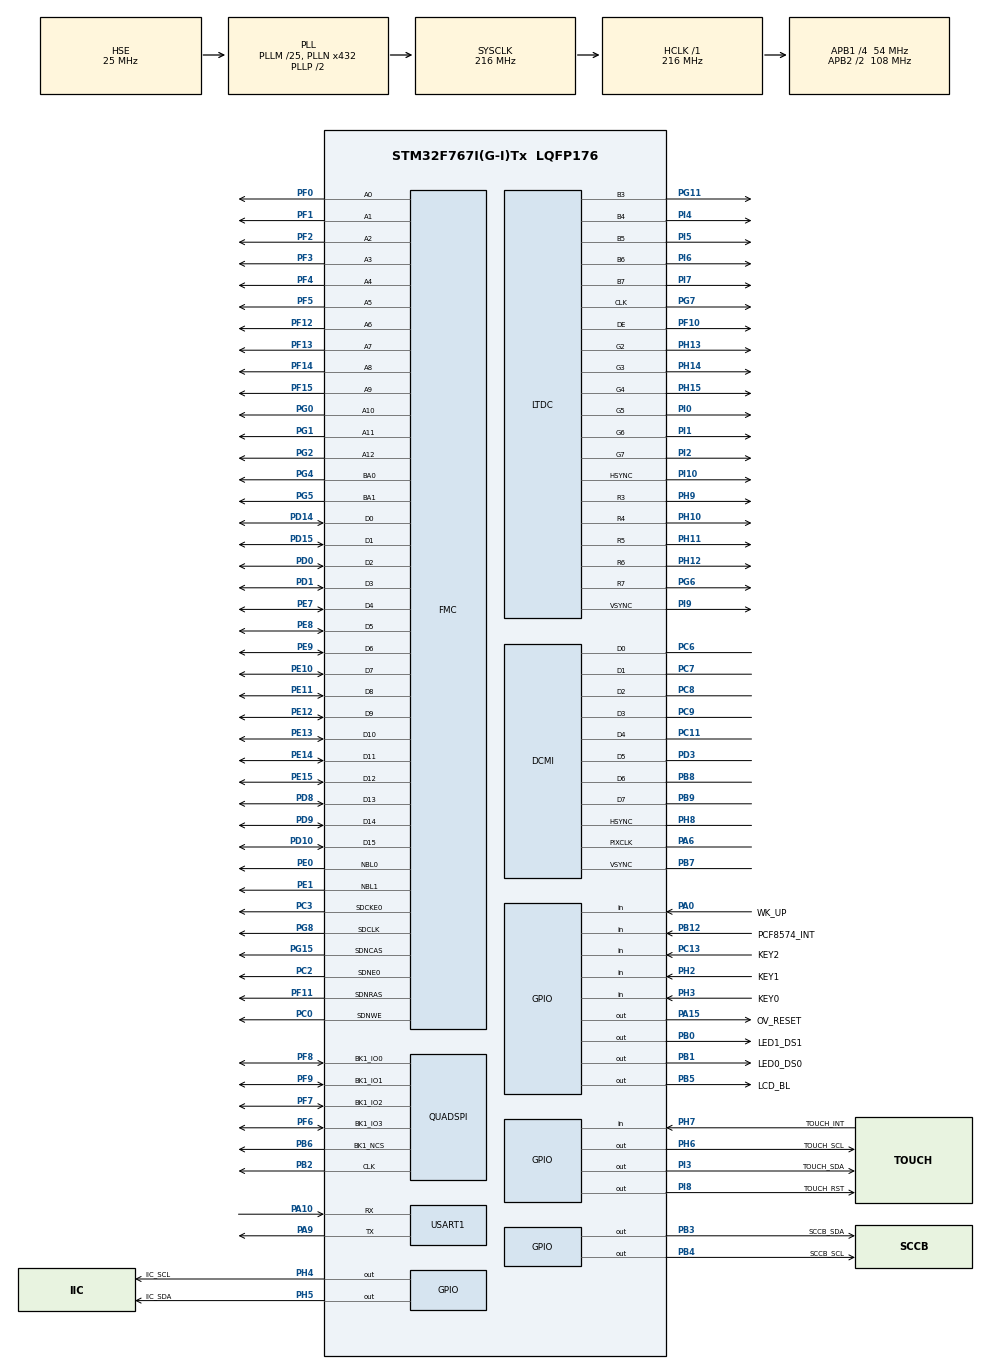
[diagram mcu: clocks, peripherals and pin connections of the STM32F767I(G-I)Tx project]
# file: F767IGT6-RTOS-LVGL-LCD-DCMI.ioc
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CORTEX_M7.default_mode_Activation=1
DCMI.HSPolarity=DCMI_HSPOLARITY_LOW
DCMI.JPEGMode=DCMI_JPEG_DISABLE
DCMI.PCKPolarity=DCMI_PCKPOLARITY_RISING
DCMI.VSPolarity=DCMI_VSPOLARITY_LOW
FMC.CASLatency1=FMC_SDRAM_CAS_LATENCY_3
FMC.ColumnBitsNumber1=FMC_SDRAM_COLUMN_BITS_NUM_9
FMC.ExitSelfRefreshDelay1=8
FMC.LoadToActiveDelay1=2
FMC.RCDDelay1=2
FMC.RPDelay1=2
FMC.ReadBurst1=FMC_SDRAM_RBURST_ENABLE
FMC.ReadPipeDelay1=FMC_SDRAM_RPIPE_DELAY_1
FMC.RowBitsNumber1=FMC_SDRAM_ROW_BITS_NUM_13
FMC.RowCycleDelay1=6
FMC.SDBank1=FMC_SDRAM_BANK1
FMC.SDClockPeriod1=FMC_SDRAM_CLOCK_PERIOD_2
FMC.SelfRefreshTime1=6
FMC.WriteRecoveryTime1=2
FMC.WriteProtection1=FMC_SDRAM_WRITE_PROTECTION_DISABLE
LTDC.ActiveW=1024
LTDC.ActiveH=600
LTDC.HSync=20
LTDC.HBP=140
LTDC.HFP=160
LTDC.VSync=3
LTDC.VBP=20
LTDC.VFP=12
LTDC.Layers=1
LTDC.WindowX0_L0=0
LTDC.WindowX1_L0=424
LTDC.WindowY0_L0=0
LTDC.WindowY1_L0=600
LTDC.PixelFormat_L0=LTDC_PIXEL_FORMAT_RGB565
LTDC.Alpha_L0=255
LTDC.Alpha0_L0=0
LTDC.BlendingFactor1_L0=LTDC_BLENDING_FACTOR1_PAxCA
LTDC.BlendingFactor2_L0=LTDC_BLENDING_FACTOR2_PAxCA
LTDC.FBStartAdress_L0=0xC0000000
LTDC.ImageWidth_L0=424
LTDC.ImageHeight_L0=600
LTDC.WindowX0_L1=424
LTDC.WindowX1_L1=1024
LTDC.WindowY0_L1=0
LTDC.WindowY1_L1=600
LTDC.PixelFormat_L1=LTDC_PIXEL_FORMAT_RGB565
LTDC.Alpha_L1=255
LTDC.Alpha0_L1=0
LTDC.BlendingFactor1_L1=LTDC_BLENDING_FACTOR1_PAxCA
LTDC.BlendingFactor2_L1=LTDC_BLENDING_FACTOR2_PAxCA
LTDC.FBStartAdress_L1=0xC0140000
LTDC.ImageWidth_L1=600
LTDC.ImageHeight_L1=600
Mcu.Family=STM32F7
Mcu.Name=STM32F767I(G-I)Tx
Mcu.Package=LQFP176
NVIC.DCMI_IRQn=true\:2\:0\:false\:false\:true\:true\:true\:true
NVIC.DMA2_Stream1_IRQn=true\:2\:0\:false\:false\:true\:true\:true\:true
NVIC.PriorityGroup=NVIC_PRIORITYGROUP_4
NVIC.TIM7_IRQn=true\:15\:0\:false\:false\:true\:false\:true\:true
NVIC.TimeBase=TIM7_IRQn
NVIC.TimeBaseIP=TIM7
PA0/WKUP.GPIO_Label=WK_UP
PA0/WKUP.GPIO_PuPd=GPIO_PULLDOWN
PA0/WKUP.Signal=GPIO_Input
PA10.Mode=Asynchronous
PA10.Signal=USART1_RX
PA13.Mode=Serial_Wire
PA13.Signal=SYS_JTMS-SWDIO
PA14.Mode=Serial_Wire
PA14.Signal=SYS_JTCK-SWCLK
PA15.GPIO_Label=OV_RESET
PA15.GPIO_PuPd=GPIO_PULLUP
PA15.GPIO_Speed=GPIO_SPEED_FREQ_HIGH
PA15.Signal=GPIO_Output
PA6.Mode=Slave_8_bits_External_Synchro
PA6.GPIO_Mode=GPIO_MODE_AF_PP
PA6.GPIO_PuPd=GPIO_PULLUP
PA6.GPIO_Speed=GPIO_SPEED_FREQ_VERY_HIGH
PA6.Signal=DCMI_PIXCLK
PA9.Mode=Asynchronous
PA9.Signal=USART1_TX
PB0.GPIO_Label=LED1_DS1
PB0.GPIO_PuPd=GPIO_PULLUP
PB0.GPIO_Speed=GPIO_SPEED_FREQ_HIGH
PB0.Signal=GPIO_Output
PB1.GPIO_Label=LED0_DS0
PB1.GPIO_PuPd=GPIO_PULLUP
PB1.GPIO_Speed=GPIO_SPEED_FREQ_HIGH
PB1.Signal=GPIO_Output
PB12.GPIO_Label=PCF8574_INT
PB12.GPIO_PuPd=GPIO_PULLUP
PB12.Signal=GPIO_Input
PB2.Mode=Single Bank 1
PB2.Signal=QUADSPI_CLK
PB3.GPIO_Label=SCCB_SDA
PB3.GPIO_PuPd=GPIO_PULLUP
PB3.GPIO_Speed=GPIO_SPEED_FREQ_HIGH
PB3.Signal=GPIO_Output
PB4.GPIO_Label=SCCB_SCL
PB4.GPIO_PuPd=GPIO_PULLUP
PB4.GPIO_Speed=GPIO_SPEED_FREQ_HIGH
PB4.Signal=GPIO_Output
PB5.GPIO_Label=LCD_BL
PB5.GPIO_PuPd=GPIO_PULLUP
PB5.GPIO_Speed=GPIO_SPEED_FREQ_HIGH
PB5.Signal=GPIO_Output
PB6.Mode=Single Bank 1
PB6.Signal=QUADSPI_BK1_NCS
PB7.Mode=Slave_8_bits_External_Synchro
PB7.GPIO_Mode=GPIO_MODE_AF_PP
PB7.GPIO_PuPd=GPIO_PULLUP
PB7.GPIO_Speed=GPIO_SPEED_FREQ_VERY_HIGH
PB7.Signal=DCMI_VSYNC
PB8.Mode=Slave_8_bits_External_Synchro
PB8.GPIO_Mode=GPIO_MODE_AF_PP
PB8.GPIO_PuPd=GPIO_PULLUP
PB8.GPIO_Speed=GPIO_SPEED_FREQ_VERY_HIGH
PB8.Signal=DCMI_D6
PB9.Mode=Slave_8_bits_External_Synchro
PB9.GPIO_Mode=GPIO_MODE_AF_PP
PB9.GPIO_PuPd=GPIO_PULLUP
PB9.GPIO_Speed=GPIO_SPEED_FREQ_VERY_HIGH
PB9.Signal=DCMI_D7
PC0.Signal=FMC_SDNWE
PC11.Mode=Slave_8_bits_External_Synchro
PC11.GPIO_Mode=GPIO_MODE_AF_PP
PC11.GPIO_PuPd=GPIO_PULLUP
PC11.GPIO_Speed=GPIO_SPEED_FREQ_VERY_HIGH
PC11.Signal=DCMI_D4
PC13.GPIO_Label=KEY2
PC13.GPIO_PuPd=GPIO_PULLUP
PC13.Signal=GPIO_Input
PC14/OSC32_IN.Mode=LSE-External-Oscillator
PC14/OSC32_IN.Signal=RCC_OSC32_IN
PC15/OSC32_OUT.Mode=LSE-External-Oscillator
PC15/OSC32_OUT.Signal=RCC_OSC32_OUT
PC2.Mode=SdramChipSelect1_1
PC2.Signal=FMC_SDNE0
PC3.Mode=SdramChipSelect1_1
PC3.Signal=FMC_SDCKE0
PC6.Mode=Slave_8_bits_External_Synchro
PC6.GPIO_Mode=GPIO_MODE_AF_PP
PC6.GPIO_PuPd=GPIO_PULLUP
PC6.GPIO_Speed=GPIO_SPEED_FREQ_VERY_HIGH
PC6.Signal=DCMI_D0
PC7.Mode=Slave_8_bits_External_Synchro
PC7.GPIO_Mode=GPIO_MODE_AF_PP
PC7.GPIO_PuPd=GPIO_PULLUP
PC7.GPIO_Speed=GPIO_SPEED_FREQ_VERY_HIGH
PC7.Signal=DCMI_D1
PC8.Mode=Slave_8_bits_External_Synchro
PC8.GPIO_Mode=GPIO_MODE_AF_PP
PC8.GPIO_PuPd=GPIO_PULLUP
PC8.GPIO_Speed=GPIO_SPEED_FREQ_VERY_HIGH
PC8.Signal=DCMI_D2
PC9.Mode=Slave_8_bits_External_Synchro
PC9.GPIO_Mode=GPIO_MODE_AF_PP
PC9.GPIO_PuPd=GPIO_PULLUP
PC9.GPIO_Speed=GPIO_SPEED_FREQ_VERY_HIGH
PC9.Signal=DCMI_D3
PD0.Signal=FMC_D2_DA2
PD1.Signal=FMC_D3_DA3
PD10.Signal=FMC_D15_DA15
PD14.Signal=FMC_D0_DA0
PD15.Signal=FMC_D1_DA1
PD3.Mode=Slave_8_bits_External_Synchro
PD3.GPIO_Mode=GPIO_MODE_AF_PP
PD3.GPIO_PuPd=GPIO_PULLUP
PD3.GPIO_Speed=GPIO_SPEED_FREQ_VERY_HIGH
PD3.Signal=DCMI_D5
PD8.Signal=FMC_D13_DA13
PD9.Signal=FMC_D14_DA14
PE0.Signal=FMC_NBL0
PE1.Signal=FMC_NBL1
PE10.Signal=FMC_D7_DA7
PE11.Signal=FMC_D8_DA8
PE12.Signal=FMC_D9_DA9
PE13.Signal=FMC_D10_DA10
PE14.Signal=FMC_D11_DA11
PE15.Signal=FMC_D12_DA12
PE7.Signal=FMC_D4_DA4
PE8.Signal=FMC_D5_DA5
PE9.Signal=FMC_D6_DA6
PF0.Signal=FMC_A0
PF1.Signal=FMC_A1
PF10.Mode=RGB565
PF10.GPIO_Mode=GPIO_MODE_AF_PP
PF10.GPIO_PuPd=GPIO_NOPULL
PF10.GPIO_Speed=GPIO_SPEED_FREQ_VERY_HIGH
PF10.Signal=LTDC_DE
PF11.Signal=FMC_SDNRAS
PF12.Signal=FMC_A6
PF13.Signal=FMC_A7
PF14.Signal=FMC_A8
PF15.Signal=FMC_A9
PF2.Signal=FMC_A2
PF3.Signal=FMC_A3
PF4.Signal=FMC_A4
PF5.Signal=FMC_A5
PF6.Mode=Single Bank 1
PF6.Signal=QUADSPI_BK1_IO3
PF7.Mode=Single Bank 1
PF7.Signal=QUADSPI_BK1_IO2
PF8.Mode=Single Bank 1
PF8.Signal=QUADSPI_BK1_IO0
PF9.Mode=Single Bank 1
PF9.Signal=QUADSPI_BK1_IO1
PG0.Signal=FMC_A10
PG1.Signal=FMC_A11
PG11.Mode=RGB565
PG11.GPIO_Mode=GPIO_MODE_AF_PP
PG11.GPIO_PuPd=GPIO_NOPULL
PG11.GPIO_Speed=GPIO_SPEED_FREQ_VERY_HIGH
PG11.Signal=LTDC_B3
PG15.Signal=FMC_SDNCAS
PG2.Signal=FMC_A12
PG4.Signal=FMC_A14_BA0
PG5.Signal=FMC_A15_BA1
PG6.Mode=RGB565
PG6.GPIO_Mode=GPIO_MODE_AF_PP
PG6.GPIO_PuPd=GPIO_NOPULL
PG6.GPIO_Speed=GPIO_SPEED_FREQ_VERY_HIGH
PG6.Signal=LTDC_R7
PG7.Mode=RGB565
PG7.GPIO_Mode=GPIO_MODE_AF_PP
PG7.GPIO_PuPd=GPIO_NOPULL
PG7.GPIO_Speed=GPIO_SPEED_FREQ_VERY_HIGH
PG7.Signal=LTDC_CLK
PG8.Signal=FMC_SDCLK
PH0/OSC_IN.Mode=HSE-External-Oscillator
PH0/OSC_IN.Signal=RCC_OSC_IN
PH1/OSC_OUT.Mode=HSE-External-Oscillator
PH1/OSC_OUT.Signal=RCC_OSC_OUT
PH10.Mode=RGB565
PH10.GPIO_Mode=GPIO_MODE_AF_PP
PH10.GPIO_PuPd=GPIO_NOPULL
PH10.GPIO_Speed=GPIO_SPEED_FREQ_VERY_HIGH
PH10.Signal=LTDC_R4
PH11.Mode=RGB565
PH11.GPIO_Mode=GPIO_MODE_AF_PP
PH11.GPIO_PuPd=GPIO_NOPULL
PH11.GPIO_Speed=GPIO_SPEED_FREQ_VERY_HIGH
PH11.Signal=LTDC_R5
PH12.Mode=RGB565
PH12.GPIO_Mode=GPIO_MODE_AF_PP
PH12.GPIO_PuPd=GPIO_NOPULL
PH12.GPIO_Speed=GPIO_SPEED_FREQ_VERY_HIGH
PH12.Signal=LTDC_R6
PH13.Mode=RGB565
PH13.GPIO_Mode=GPIO_MODE_AF_PP
PH13.GPIO_PuPd=GPIO_NOPULL
PH13.GPIO_Speed=GPIO_SPEED_FREQ_VERY_HIGH
PH13.Signal=LTDC_G2
PH14.Mode=RGB565
PH14.GPIO_Mode=GPIO_MODE_AF_PP
PH14.GPIO_PuPd=GPIO_NOPULL
PH14.GPIO_Speed=GPIO_SPEED_FREQ_VERY_HIGH
PH14.Signal=LTDC_G3
PH15.Mode=RGB565
PH15.GPIO_Mode=GPIO_MODE_AF_PP
PH15.GPIO_PuPd=GPIO_NOPULL
PH15.GPIO_Speed=GPIO_SPEED_FREQ_VERY_HIGH
PH15.Signal=LTDC_G4
PH2.GPIO_Label=KEY1
PH2.GPIO_PuPd=GPIO_PULLUP
PH2.Signal=GPIO_Input
PH3.GPIO_Label=KEY0
PH3.GPIO_PuPd=GPIO_PULLUP
PH3.Signal=GPIO_Input
PH4.GPIO_Label=IIC_SCL
PH4.GPIO_PuPd=GPIO_PULLUP
PH4.GPIO_Speed=GPIO_SPEED_FREQ_HIGH
PH4.Signal=GPIO_Output
PH5.GPIO_Label=IIC_SDA
PH5.GPIO_PuPd=GPIO_PULLUP
PH5.GPIO_Speed=GPIO_SPEED_FREQ_HIGH
PH5.Signal=GPIO_Output
PH8.Mode=Slave_8_bits_External_Synchro
PH8.GPIO_Mode=GPIO_MODE_AF_PP
PH8.GPIO_PuPd=GPIO_PULLUP
PH8.GPIO_Speed=GPIO_SPEED_FREQ_VERY_HIGH
PH8.Signal=DCMI_HSYNC
PH9.Mode=RGB565
PH9.GPIO_Mode=GPIO_MODE_AF_PP
PH9.GPIO_PuPd=GPIO_NOPULL
PH9.GPIO_Speed=GPIO_SPEED_FREQ_VERY_HIGH
PH9.Signal=LTDC_R3
PI0.Mode=RGB565
PI0.GPIO_Mode=GPIO_MODE_AF_PP
PI0.GPIO_PuPd=GPIO_NOPULL
PI0.GPIO_Speed=GPIO_SPEED_FREQ_VERY_HIGH
PI0.Signal=LTDC_G5
PI1.Mode=RGB565
PI1.GPIO_Mode=GPIO_MODE_AF_PP
PI1.GPIO_PuPd=GPIO_NOPULL
PI1.GPIO_Speed=GPIO_SPEED_FREQ_VERY_HIGH
PI1.Signal=LTDC_G6
PI10.Mode=RGB565
PI10.GPIO_Mode=GPIO_MODE_AF_PP
PI10.GPIO_PuPd=GPIO_NOPULL
PI10.GPIO_Speed=GPIO_SPEED_FREQ_VERY_HIGH
PI10.Signal=LTDC_HSYNC
PI2.Mode=RGB565
PI2.GPIO_Mode=GPIO_MODE_AF_PP
PI2.GPIO_PuPd=GPIO_NOPULL
PI2.GPIO_Speed=GPIO_SPEED_FREQ_VERY_HIGH
PI2.Signal=LTDC_G7
PI4.Mode=RGB565
PI4.GPIO_Mode=GPIO_MODE_AF_PP
PI4.GPIO_PuPd=GPIO_NOPULL
PI4.GPIO_Speed=GPIO_SPEED_FREQ_VERY_HIGH
PI4.Signal=LTDC_B4
PI5.Mode=RGB565
PI5.GPIO_Mode=GPIO_MODE_AF_PP
PI5.GPIO_PuPd=GPIO_NOPULL
PI5.GPIO_Speed=GPIO_SPEED_FREQ_VERY_HIGH
PI5.Signal=LTDC_B5
PI6.Mode=RGB565
PI6.GPIO_Mode=GPIO_MODE_AF_PP
PI6.GPIO_PuPd=GPIO_NOPULL
PI6.GPIO_Speed=GPIO_SPEED_FREQ_VERY_HIGH
PI6.Signal=LTDC_B6
PI7.Mode=RGB565
PI7.GPIO_Mode=GPIO_MODE_AF_PP
PI7.GPIO_PuPd=GPIO_NOPULL
PI7.GPIO_Speed=GPIO_SPEED_FREQ_VERY_HIGH
PI7.Signal=LTDC_B7
PI9.Mode=RGB565
PI9.GPIO_Mode=GPIO_MODE_AF_PP
PI9.GPIO_PuPd=GPIO_NOPULL
PI9.GPIO_Speed=GPIO_SPEED_FREQ_VERY_HIGH
PI9.Signal=LTDC_VSYNC
PH6.GPIO_Label=TOUCH_SCL
PH6.GPIO_PuPd=GPIO_PULLUP
PH6.GPIO_Speed=GPIO_SPEED_FREQ_HIGH
PH6.Signal=GPIO_Output
PI3.GPIO_Label=TOUCH_SDA
PI3.GPIO_PuPd=GPIO_PULLUP
PI3.GPIO_Speed=GPIO_SPEED_FREQ_HIGH
PI3.Signal=GPIO_Output
PI8.GPIO_Label=TOUCH_RST
PI8.GPIO_PuPd=GPIO_NOPULL
PI8.GPIO_Speed=GPIO_SPEED_FREQ_HIGH
PI8.Signal=GPIO_Output
PH7.GPIO_Label=TOUCH_INT
PH7.GPIO_PuPd=GPIO_PULLUP
PH7.GPIO_Speed=GPIO_SPEED_FREQ_LOW
PH7.Signal=GPIO_Input
ProjectManager.HeapSize=0x200
ProjectManager.StackSize=0x400
ProjectManager.TargetToolchain=MDK-ARM V5.32
QUADSPI.ChipSelectHighTime=QSPI_CS_HIGH_TIME_4_CYCLE
QUADSPI.ClockMode=QSPI_CLOCK_MODE_0
QUADSPI.ClockPrescaler=2
QUADSPI.DualFlash=QSPI_DUALFLASH_DISABLE
QUADSPI.FifoThreshold=4
QUADSPI.FlashID=QSPI_FLASH_ID_1
QUADSPI.FlashSize=24
QUADSPI.SampleShifting=QSPI_SAMPLE_SHIFTING_HALFCYCLE
RCC.AHBFreq_Value=216000000
RCC.APB1CLKDivider=RCC_HCLK_DIV4
RCC.APB1Freq_Value=54000000
RCC.APB1TimFreq_Value=108000000
RCC.APB2CLKDivider=RCC_HCLK_DIV2
RCC.APB2Freq_Value=108000000
RCC.APB2TimFreq_Value=216000000
RCC.CortexFreq_Value=216000000
RCC.HCLKFreq_Value=216000000
RCC.HSE_VALUE=25000000
RCC.HSI_VALUE=16000000
RCC.PLLM=25
RCC.PLLN=432
RCC.PLLSAIDivR=RCC_PLLSAIDIVR_4
RCC.PLLSAIN=320
RCC.PLLSAIP=RCC_PLLSAIP_DIV2
RCC.PLLSAIQ=2
RCC.PLLSAIR=2
RCC.PLLSourceVirtual=RCC_PLLSOURCE_HSE
RCC.SYSCLKFreq_VALUE=216000000
RCC.SYSCLKSource=RCC_SYSCLKSOURCE_PLLCLK
RCC.USBFreq_Value=216000000
RCC.VCOOutputFreq_Value=432000000
SH.FMC_A0.0=FMC_A0,13b-sda1
SH.FMC_A1.0=FMC_A1,13b-sda1
SH.FMC_A10.0=FMC_A10,13b-sda1
SH.FMC_A11.0=FMC_A11,13b-sda1
SH.FMC_A12.0=FMC_A12,13b-sda1
SH.FMC_A14_BA0.0=FMC_BA0,FourSdramBanks1
SH.FMC_A15_BA1.0=FMC_BA1,FourSdramBanks1
SH.FMC_A2.0=FMC_A2,13b-sda1
SH.FMC_A3.0=FMC_A3,13b-sda1
SH.FMC_A4.0=FMC_A4,13b-sda1
SH.FMC_A5.0=FMC_A5,13b-sda1
SH.FMC_A6.0=FMC_A6,13b-sda1
SH.FMC_A7.0=FMC_A7,13b-sda1
SH.FMC_A8.0=FMC_A8,13b-sda1
SH.FMC_A9.0=FMC_A9,13b-sda1
SH.FMC_D0_DA0.0=FMC_D0,sd-16b-d1
SH.FMC_D10_DA10.0=FMC_D10,sd-16b-d1
SH.FMC_D11_DA11.0=FMC_D11,sd-16b-d1
SH.FMC_D12_DA12.0=FMC_D12,sd-16b-d1
SH.FMC_D13_DA13.0=FMC_D13,sd-16b-d1
SH.FMC_D14_DA14.0=FMC_D14,sd-16b-d1
SH.FMC_D15_DA15.0=FMC_D15,sd-16b-d1
SH.FMC_D1_DA1.0=FMC_D1,sd-16b-d1
SH.FMC_D2_DA2.0=FMC_D2,sd-16b-d1
SH.FMC_D3_DA3.0=FMC_D3,sd-16b-d1
SH.FMC_D4_DA4.0=FMC_D4,sd-16b-d1
SH.FMC_D5_DA5.0=FMC_D5,sd-16b-d1
SH.FMC_D6_DA6.0=FMC_D6,sd-16b-d1
SH.FMC_D7_DA7.0=FMC_D7,sd-16b-d1
SH.FMC_D8_DA8.0=FMC_D8,sd-16b-d1
SH.FMC_D9_DA9.0=FMC_D9,sd-16b-d1
SH.FMC_NBL0.0=FMC_NBL0,Sd2ByteEnable1
SH.FMC_NBL1.0=FMC_NBL1,Sd2ByteEnable1
SH.FMC_SDCLK.0=FMC_SDCLK,13b-sda1
SH.FMC_SDNCAS.0=FMC_SDNCAS,13b-sda1
SH.FMC_SDNRAS.0=FMC_SDNRAS,13b-sda1
SH.FMC_SDNWE.0=FMC_SDNWE,13b-sda1
USART1.VirtualMode-Asynchronous=VM_ASYNC
VP_DMA2D_VS_DMA2D.Mode=DMA2D_Activate
VP_SYS_VS_tim7.Mode=TIM7
board=custom

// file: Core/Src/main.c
/* USER CODE BEGIN Header */
/**
  ******************************************************************************
  * @file           : main.c
  * @brief          : Main program body
  ******************************************************************************
  * @attention
  *
  * Copyright (c) 2026 STMicroelectronics.
  * All rights reserved.
  *
  * This software is licensed under terms that can be found in the LICENSE file
  * in the root directory of this software component.
  * If no LICENSE file comes with this software, it is provided AS-IS.
  *
  ******************************************************************************
  */
/* USER CODE END Header */
#include "main.h"
#include "dcmi.h"
#include "dma2d.h"
#include "ltdc.h"
#include "quadspi.h"
#include "usart.h"
#include "gpio.h"
#include "fmc.h"

/* USER CODE BEGIN Includes */
#include "FreeRTOS.h"
#include "task.h"
#include "app_tasks.h"
#include "display_config.h"
/* USER CODE END Includes */

void SystemClock_Config(void);
static void MPU_Config(void);

int main(void)
{

  /* MPU Configuration--------------------------------------------------------*/
  MPU_Config();

  /* MCU Configuration--------------------------------------------------------*/

  /* Reset of all peripherals, Initializes the Flash interface and the Systick. */
  HAL_Init();

  /* Configure the system clock */
  SystemClock_Config();

  /* Initialize all configured peripherals */
  MX_GPIO_Init();
  MX_DCMI_Init();
  MX_DMA2D_Init();
  MX_FMC_Init();
  MX_LTDC_Init();
  MX_QUADSPI_Init();
  MX_USART1_UART_Init();
  /* USER CODE BEGIN 2 */
  /* LED0(DS0/PB1)、LED1(DS1/PB0) 低电平点亮，上电先熄灭 */
  HAL_GPIO_WritePin(GPIOB, LED0_DS0_Pin | LED1_DS1_Pin, GPIO_PIN_SET);

  /* 清屏：SDRAM 上电/复位后内容不确定，而 LTDC 已在扫描 0xC0000000，
   * 若直接点背光会看到上一次运行的残留画面。先把 LVGL 图层 0 的
   * 1024x600x2B 帧缓冲刷成黑色，再打开背光 */
  {
    uint32_t *fb = (uint32_t *)DISPLAY_FB_ADDR;
    uint32_t i;

    for (i = 0U; i < (DISPLAY_FB_BYTES / 4U); i++)
    {
      fb[i] = 0x00000000U;
    }
  }

  /* LCD 背光 PB5 高电平点亮，必须在清屏之后 */
  HAL_GPIO_WritePin(LCD_BL_GPIO_Port, LCD_BL_Pin, GPIO_PIN_SET);

  /* 创建应用任务并启动调度器，正常情况下不再返回 */
  AppTasks_Init();
  vTaskStartScheduler();
  /* USER CODE END 2 */

  /* Infinite loop */
  while (1)
  {

  }
}

void SystemClock_Config(void)
{
  RCC_OscInitTypeDef RCC_OscInitStruct = {0};
  RCC_ClkInitTypeDef RCC_ClkInitStruct = {0};

  /** Configure LSE Drive Capability
  */
  HAL_PWR_EnableBkUpAccess();

  /** Configure the main internal regulator output voltage
  */
  __HAL_RCC_PWR_CLK_ENABLE();
  __HAL_PWR_VOLTAGESCALING_CONFIG(PWR_REGULATOR_VOLTAGE_SCALE1);

  /** Initializes the RCC Oscillators according to the specified parameters
  * in the RCC_OscInitTypeDef structure.
  */
  RCC_OscInitStruct.OscillatorType = RCC_OSCILLATORTYPE_HSE;
  RCC_OscInitStruct.HSEState = RCC_HSE_ON;
  RCC_OscInitStruct.PLL.PLLState = RCC_PLL_ON;
  RCC_OscInitStruct.PLL.PLLSource = RCC_PLLSOURCE_HSE;
  RCC_OscInitStruct.PLL.PLLM = 25;
  RCC_OscInitStruct.PLL.PLLN = 432;
  RCC_OscInitStruct.PLL.PLLP = RCC_PLLP_DIV2;
  RCC_OscInitStruct.PLL.PLLQ = 2;
  RCC_OscInitStruct.PLL.PLLR = 2;
  if (HAL_RCC_OscConfig(&RCC_OscInitStruct) != HAL_OK)
  {
    Error_Handler();
  }

  /** Activate the Over-Drive mode
  */
  if (HAL_PWREx_EnableOverDrive() != HAL_OK)
  {
    Error_Handler();
  }

  /** Initializes the CPU, AHB and APB buses clocks
  */
  RCC_ClkInitStruct.ClockType = RCC_CLOCKTYPE_HCLK|RCC_CLOCKTYPE_SYSCLK
                              |RCC_CLOCKTYPE_PCLK1|RCC_CLOCKTYPE_PCLK2;
  RCC_ClkInitStruct.SYSCLKSource = RCC_SYSCLKSOURCE_PLLCLK;
  RCC_ClkInitStruct.AHBCLKDivider = RCC_SYSCLK_DIV1;
  RCC_ClkInitStruct.APB1CLKDivider = RCC_HCLK_DIV4;
  RCC_ClkInitStruct.APB2CLKDivider = RCC_HCLK_DIV2;

  if (HAL_RCC_ClockConfig(&RCC_ClkInitStruct, FLASH_LATENCY_7) != HAL_OK)
  {
    Error_Handler();
  }
}

 /* MPU Configuration */

void MPU_Config(void)
{
  MPU_Region_InitTypeDef MPU_InitStruct = {0};

  /* Disables the MPU */
  HAL_MPU_Disable();

  /** Region 0 : FMC 数据区 0x60000000-0x63FFFFFF
  */
  MPU_InitStruct.Enable = MPU_REGION_ENABLE;
  MPU_InitStruct.Number = MPU_REGION_NUMBER0;
  MPU_InitStruct.BaseAddress = 0x60000000;
  MPU_InitStruct.Size = MPU_REGION_SIZE_64MB;
  MPU_InitStruct.SubRegionDisable = 0x00;
  MPU_InitStruct.TypeExtField = MPU_TEX_LEVEL0;
  MPU_InitStruct.AccessPermission = MPU_REGION_FULL_ACCESS;
  MPU_InitStruct.DisableExec = MPU_INSTRUCTION_ACCESS_DISABLE;
  MPU_InitStruct.IsShareable = MPU_ACCESS_NOT_SHAREABLE;
  MPU_InitStruct.IsCacheable = MPU_ACCESS_CACHEABLE;
  MPU_InitStruct.IsBufferable = MPU_ACCESS_BUFFERABLE;
  HAL_MPU_ConfigRegion(&MPU_InitStruct);

  /** Region 1 : SDRAM 0xC0000000-0xC1FFFFFF(32MB)
  *  全访问 + 非缓存，保证 CPU 与 LTDC/DCMI/DMA2D 看到同一份数据
  */
  MPU_InitStruct.Number = MPU_REGION_NUMBER1;
  MPU_InitStruct.BaseAddress = 0xC0000000;
  MPU_InitStruct.Size = MPU_REGION_SIZE_32MB;
  MPU_InitStruct.SubRegionDisable = 0x00;
  MPU_InitStruct.TypeExtField = MPU_TEX_LEVEL1;
  MPU_InitStruct.AccessPermission = MPU_REGION_FULL_ACCESS;
  MPU_InitStruct.DisableExec = MPU_INSTRUCTION_ACCESS_DISABLE;
  MPU_InitStruct.IsShareable = MPU_ACCESS_SHAREABLE;
  MPU_InitStruct.IsCacheable = MPU_ACCESS_NOT_CACHEABLE;
  MPU_InitStruct.IsBufferable = MPU_ACCESS_NOT_BUFFERABLE;
  HAL_MPU_ConfigRegion(&MPU_InitStruct);

  /* Enables the MPU */
  HAL_MPU_Enable(MPU_PRIVILEGED_DEFAULT);

}

void HAL_TIM_PeriodElapsedCallback(TIM_HandleTypeDef *htim)
{
  if (htim->Instance == TIM7)
  {
    HAL_IncTick();
  }
}

void Error_Handler(void)
{
  __disable_irq();
  while (1)
  {
  }
}
